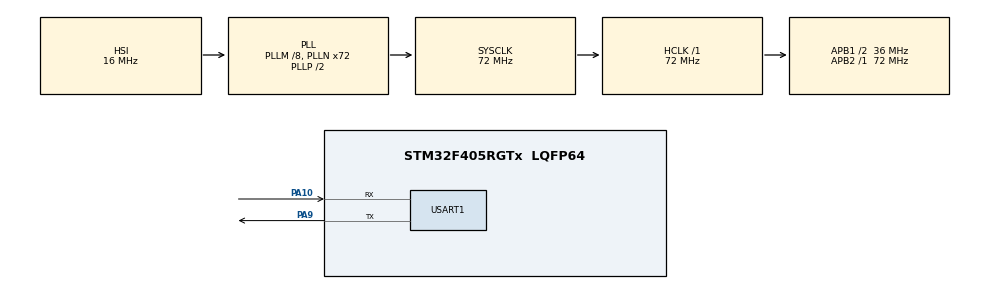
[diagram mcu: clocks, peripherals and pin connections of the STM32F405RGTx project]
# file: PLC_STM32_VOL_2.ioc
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Dma.Request0=USART1_TX
Dma.USART1_TX.0.Direction=DMA_MEMORY_TO_PERIPH
Dma.USART1_TX.0.FIFOMode=DMA_FIFOMODE_DISABLE
Dma.USART1_TX.0.Instance=DMA2_Stream7
Dma.USART1_TX.0.MemDataAlignment=DMA_MDATAALIGN_BYTE
Dma.USART1_TX.0.MemInc=DMA_MINC_ENABLE
Dma.USART1_TX.0.Mode=DMA_NORMAL
Dma.USART1_TX.0.PeriphDataAlignment=DMA_PDATAALIGN_BYTE
Dma.USART1_TX.0.PeriphInc=DMA_PINC_DISABLE
Dma.USART1_TX.0.Priority=DMA_PRIORITY_LOW
Mcu.Family=STM32F4
Mcu.Name=STM32F405RGTx
Mcu.Package=LQFP64
NVIC.DMA2_Stream7_IRQn=true\:0\:0\:false\:false\:true\:false\:true\:true
NVIC.PriorityGroup=NVIC_PRIORITYGROUP_4
NVIC.TIM1_UP_TIM10_IRQn=true\:0\:0\:false\:false\:true\:true\:true\:true
NVIC.USART1_IRQn=true\:0\:0\:false\:false\:true\:true\:true\:true
PA10.Mode=Asynchronous
PA10.Signal=USART1_RX
PA9.Mode=Asynchronous
PA9.Signal=USART1_TX
ProjectManager.HeapSize=0x200
ProjectManager.StackSize=0x400
ProjectManager.TargetToolchain=MDK-ARM V5.32
RCC.48MHZClocksFreq_Value=36000000
RCC.AHBFreq_Value=72000000
RCC.APB1CLKDivider=RCC_HCLK_DIV2
RCC.APB1Freq_Value=36000000
RCC.APB1TimFreq_Value=72000000
RCC.APB2Freq_Value=72000000
RCC.APB2TimFreq_Value=72000000
RCC.CortexFreq_Value=72000000
RCC.HCLKFreq_Value=72000000
RCC.HSE_VALUE=25000000
RCC.HSI_VALUE=16000000
RCC.LSE_VALUE=32768
RCC.PLLM=8
RCC.PLLN=72
RCC.SYSCLKFreq_VALUE=72000000
RCC.SYSCLKSource=RCC_SYSCLKSOURCE_PLLCLK
RCC.VCOOutputFreq_Value=144000000
TIM10.Period=50
TIM10.Prescaler=71
USART1.VirtualMode=VM_ASYNC
VP_TIM10_VS_ClockSourceINT.Mode=Enable_Timer
board=custom

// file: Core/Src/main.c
/* USER CODE BEGIN Header */
/**
  ******************************************************************************
  * @file           : main.c
  * @brief          : Main program body
  ******************************************************************************
  * @attention
  *
  * Copyright (c) 2023 STMicroelectronics.
  * All rights reserved.
  *
  * This software is licensed under terms that can be found in the LICENSE file
  * in the root directory of this software component.
  * If no LICENSE file comes with this software, it is provided AS-IS.
  *
  ******************************************************************************
  */
/* USER CODE END Header */
#include "main.h"

/* USER CODE BEGIN Includes */
#include "hmi_interface.h"

#if MODBUS_ENABLE
#include "mb.h"
#include "mbport.h"
#include "mt_port.h"
#endif

#if DWIN_SERIAL_PORT_ENABLE
#include "DWIN_lib.h"
#include "DWIN_port.h"
#endif

/* USER CODE END Includes */

TIM_HandleTypeDef htim10;

UART_HandleTypeDef huart1;
DMA_HandleTypeDef hdma_usart1_tx;

/* USER CODE BEGIN PV */
extern t_control ctrl;
extern t_hmi_reg programs[10];
extern uint8_t start;
extern uint8_t print;
extern t_step_engine step_engine;

#if MODBUS_ENABLE
extern t_modbus_him_pack rxData;
extern t_modbus_him_pack txData;

extern uint16_t rx_data[256];
extern uint8_t rx_data_indx;

static USHORT usRegHoldingStart = REG_HOLDING_START;
static int usRegHoldingBuf[REG_HOLDING_NREGS] = { 0x0 };

static USHORT usRegInputStart = REG_INPUT_START;
static USHORT usRegInputBuf[REG_INPUT_NREGS] = { 0x0 };
#endif

#if DWIN_SERIAL_PORT_ENABLE
extern volatile USHORT  ucRegistersBuf[DWIN_SER_PDU_SIZE_MAX];
extern volatile UCHAR  ucDWINBuf[DWIN_SER_PDU_SIZE_MAX];
#endif
extern uint16_t in_count;
t_dac dac;
uint8_t is_start_pos = 0x0;

t_devices dev;
/* USER CODE END PV */

void SystemClock_Config(void);
static void MX_GPIO_Init(void);
static void MX_DMA_Init(void);
static void MX_USART1_UART_Init(void);
static void MX_TIM10_Init(void);

int main(void)
{

  /* MCU Configuration--------------------------------------------------------*/

  /* Reset of all peripherals, Initializes the Flash interface and the Systick. */
  HAL_Init();

  /* Configure the system clock */
  SystemClock_Config();

  /* Initialize all configured peripherals */
  MX_GPIO_Init();
  MX_DMA_Init();
  MX_USART1_UART_Init();
  MX_TIM10_Init();
  /* USER CODE BEGIN 2 */
	#if MODBUS_ENABLE

	MT_PORT_SetTimerModule(&htim10);
	MT_PORT_SetUartModule(&huart1);

	eMBErrorCode eStatus;
	//eStatus = eMBInit(MB_RTU, 0x0A, 0, 19200, MB_PAR_NONE);
	eStatus = eMBInit(MB_RTU, 0x01, 0, 115200, MB_PAR_NONE);
	eStatus = eMBEnable();
	if (eStatus != MB_ENOERR)
	{
	// Error handling
	}

	usRegHoldingBuf[NUM_EXE_PROGRAM] = 0x01;
	usRegHoldingBuf[STEP_ENGINE_VEL_MC] = 0x30;
	usRegHoldingBuf[STEP_ENGINE_START_POS_MS] = 0x51;

	usRegHoldingBuf[STAGE_1_POS] = 3600;
	usRegHoldingBuf[STAGE_1_VEL] = 360;

	#endif

	#if PEREPH_ENABLE
	dev.step_engine = &step_engine;

	ctrl.dev = &dev;
	ctrl.programms = programs;

	init_HMI(&ctrl);
	#endif

	#if STEP_ENGINE_ENABLE
	//HAL_DBGMCU_EnableDBGStandbyMode();
  //HAL_DBGMCU_EnableDBGStopMode();
	//DBGMCU->APB1FZ |= DBGMCU_APB1_FZ_DBG_TIM3_STOP;
	HAL_GPIO_WritePin(GPIOC, GPIO_PIN_12, GPIO_PIN_SET);

	step_engine.mode = STOP;
	step_engine.vel = SPEED_MIN;
	step_engine.accel_size = 0;
	step_engine.dir = 1;
	step_engine.engine_TIM_master = &htim3;
	step_engine.engine_TIM_slave = &htim2;

	init_step_engine(&step_engine);
	#endif

	uint8_t count = 0;

	#if DAC_ENABLE
	/* DAC init */
	dac.tim = TIM6;
	dac.dac_type = DAC;
	dac.tim_presc = 719;
	dac.tim_arr = 10;
	CMSIS_DAC_init(&dac);
	uint16_t a;
	#endif

	#if DWIN_SERIAL_PORT_ENABLE
	//DWIN_PORT_SetDMAModule(DMA2_Stream2);
	DWIN_PORT_SetUartModule(&huart1);
	//CMSIS_DMA_Init(DMA2_Stream7);
	//CMSIS_DMA_Init(DMA2_Stream2);

	//HAL_NVIC_SetPriority(USART1_IRQn, 0, 0);
	//HAL_NVIC_EnableIRQ(USART1_IRQn);

	eDWINErrorCode eStatus;
	eDWINInit(0xA5, 0, 115200, DWIN_PAR_NONE);

	eStatus = eDWINEnable();
	if (eStatus != DWIN_ENOERR)
	{
	// Error handling
	}
	#endif

	//HAL_UARTEx_ReceiveToIdle_IT(&huart1, (uint8_t *)ucDWINBuf, DWIN_SER_PDU_SIZE_MAX);

  /* USER CODE END 2 */

  /* Infinite loop */
  /* USER CODE BEGIN WHILE */
  while (1)
  {
		#if PEREPH_ENABLE
			#if DATA_USART2_TX
			cnt++;
			if (cnt >= 255) cnt = 0;
			DataWrite(cnt);
			HAL_Delay(10);
			#endif

			#if DAC_ENABLE
			//dac.dac_type->DHR12R1 = a;
			//a++;
			#endif

			#if MODBUS_ENABLE
			eHMIPoll(&ctrl, usRegHoldingBuf);
			#endif

			#if DWIN_SERIAL_PORT_ENABLE
			eHMIPoll(&ctrl, ucRegistersBuf);
			#endif
		#endif

		#if MODBUS_ENABLE
		eMBPoll();
		#endif

		#if DWIN_SERIAL_PORT_ENABLE
		eDWINPoll();
		#endif

    /* USER CODE END WHILE */

  }
}

void SystemClock_Config(void)
{
  RCC_OscInitTypeDef RCC_OscInitStruct = {0};
  RCC_ClkInitTypeDef RCC_ClkInitStruct = {0};

  /** Configure the main internal regulator output voltage
  */
  __HAL_RCC_PWR_CLK_ENABLE();
  __HAL_PWR_VOLTAGESCALING_CONFIG(PWR_REGULATOR_VOLTAGE_SCALE1);

  /** Initializes the RCC Oscillators according to the specified parameters
  * in the RCC_OscInitTypeDef structure.
  */
  RCC_OscInitStruct.OscillatorType = RCC_OSCILLATORTYPE_HSI;
  RCC_OscInitStruct.HSIState = RCC_HSI_ON;
  RCC_OscInitStruct.HSICalibrationValue = RCC_HSICALIBRATION_DEFAULT;
  RCC_OscInitStruct.PLL.PLLState = RCC_PLL_ON;
  RCC_OscInitStruct.PLL.PLLSource = RCC_PLLSOURCE_HSI;
  RCC_OscInitStruct.PLL.PLLM = 8;
  RCC_OscInitStruct.PLL.PLLN = 72;
  RCC_OscInitStruct.PLL.PLLP = RCC_PLLP_DIV2;
  RCC_OscInitStruct.PLL.PLLQ = 4;
  if (HAL_RCC_OscConfig(&RCC_OscInitStruct) != HAL_OK)
  {
    Error_Handler();
  }

  /** Initializes the CPU, AHB and APB buses clocks
  */
  RCC_ClkInitStruct.ClockType = RCC_CLOCKTYPE_HCLK|RCC_CLOCKTYPE_SYSCLK
                              |RCC_CLOCKTYPE_PCLK1|RCC_CLOCKTYPE_PCLK2;
  RCC_ClkInitStruct.SYSCLKSource = RCC_SYSCLKSOURCE_PLLCLK;
  RCC_ClkInitStruct.AHBCLKDivider = RCC_SYSCLK_DIV1;
  RCC_ClkInitStruct.APB1CLKDivider = RCC_HCLK_DIV2;
  RCC_ClkInitStruct.APB2CLKDivider = RCC_HCLK_DIV1;

  if (HAL_RCC_ClockConfig(&RCC_ClkInitStruct, FLASH_LATENCY_2) != HAL_OK)
  {
    Error_Handler();
  }
}

static void MX_TIM10_Init(void)
{

  htim10.Instance = TIM10;
  htim10.Init.Prescaler = 71;
  htim10.Init.CounterMode = TIM_COUNTERMODE_UP;
  htim10.Init.Period = 50;
  htim10.Init.ClockDivision = TIM_CLOCKDIVISION_DIV1;
  htim10.Init.AutoReloadPreload = TIM_AUTORELOAD_PRELOAD_DISABLE;
  if (HAL_TIM_Base_Init(&htim10) != HAL_OK)
  {
    Error_Handler();
  }

}

static void MX_USART1_UART_Init(void)
{

  huart1.Instance = USART1;
  huart1.Init.BaudRate = 115200;
  huart1.Init.WordLength = UART_WORDLENGTH_8B;
  huart1.Init.StopBits = UART_STOPBITS_1;
  huart1.Init.Parity = UART_PARITY_NONE;
  huart1.Init.Mode = UART_MODE_TX_RX;
  huart1.Init.HwFlowCtl = UART_HWCONTROL_NONE;
  huart1.Init.OverSampling = UART_OVERSAMPLING_16;
  if (HAL_UART_Init(&huart1) != HAL_OK)
  {
    Error_Handler();
  }

}

static void MX_DMA_Init(void)
{

  /* DMA controller clock enable */
  __HAL_RCC_DMA2_CLK_ENABLE();

  /* DMA interrupt init */
  /* DMA2_Stream7_IRQn interrupt configuration */
  HAL_NVIC_SetPriority(DMA2_Stream7_IRQn, 0, 0);
  HAL_NVIC_EnableIRQ(DMA2_Stream7_IRQn);

}

static void MX_GPIO_Init(void)
{

  /* GPIO Ports Clock Enable */
  __HAL_RCC_GPIOA_CLK_ENABLE();

}

void Error_Handler(void)
{
  __disable_irq();
  while (1)
  {
  }
}
